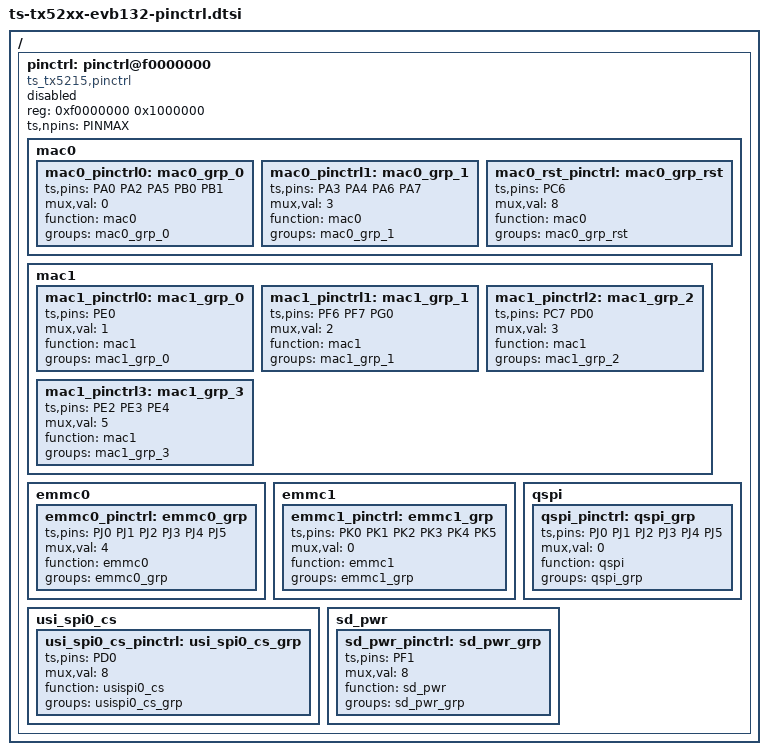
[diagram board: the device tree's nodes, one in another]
// SPDX-License-Identifier: GPL-2.0+
/*
 * Pinctrl specification for Tsingmicor Soc
 *
 * (C) Copyright 2022 - 2022, Tsingmicro, Inc.
 *
 */

#include <dt-bindings/pinctrl/pinctrl-ts-tx5215.h>
/ {
		pinctrl: pinctrl@f0000000 {
			compatible = "ts_tx5215,pinctrl";
			status = "disabled";
			reg = <0xf0000000 0x1000000>;
			ts,npins = <PINMAX>;
			mac0 {
				//MAC_EPHY_CLK MAC_TXEN MAC_RXDV MAC_MDC MAC_MDIO
				mac0_pinctrl0: mac0_grp_0 {
					ts,pins = <PA0 PA2 PA5 PB0 PB1>;
					mux,val = <0>;
					function = "mac0";
					groups = "mac0_grp_0";
				};
				//MAC_TXD0 MAC_TXD1 MAC_RXD0 MAC_RXD1
				mac0_pinctrl1: mac0_grp_1 {
					ts,pins = <PA3 PA4 PA6 PA7>;
					mux,val = <3>;
					function = "mac0";
					groups = "mac0_grp_1";
				};
				mac0_rst_pinctrl: mac0_grp_rst {
					ts,pins = <PC6>;
					mux,val = <8>;
					function = "mac0";
					groups = "mac0_grp_rst";
				};
			};

			mac1 {
				//MAC1_EPHY_CLK
				mac1_pinctrl0: mac1_grp_0 {
					ts,pins = <PE0>;
					mux,val = <1>;
					function = "mac1";
					groups = "mac1_grp_0";
				};
				//MAC1_TXEN MAC1_TXD0 MAC1_TXD1
				mac1_pinctrl1: mac1_grp_1 {
					ts,pins = <PF6 PF7 PG0>;
					mux,val = <2>;
					function = "mac1";
					groups = "mac1_grp_1";
				};
				//MAC1_MDC MAC1_MDIO
				mac1_pinctrl2: mac1_grp_2 {
					ts,pins = <PC7 PD0>;
					mux,val = <3>;
					function = "mac1";
					groups = "mac1_grp_2";
				};
				//MAC1_RXDV MAC1_RXD0 MAC1_RXD1
				mac1_pinctrl3: mac1_grp_3 {
					ts,pins = <PE2 PE3 PE4>;
					mux,val = <5>;
					function = "mac1";
					groups = "mac1_grp_3";
				};
			};

#if 0
			spi0 {
				spi0_pinctrl: spi0_grp {
					ts,pins = <PC0 PC1 PC2 PC3>;
					mux,val = <0>;
					function = "spi0";
					groups = "spi0_grp";
				};
			};
#endif
			emmc0 {
				emmc0_pinctrl: emmc0_grp {
					ts,pins = <PJ0 PJ1 PJ2 PJ3 PJ4 PJ5>;
					mux,val = <4>;
					function = "emmc0";
					groups = "emmc0_grp";
				};
			};

			emmc1 {
				emmc1_pinctrl: emmc1_grp {
					ts,pins = <PK0 PK1 PK2 PK3 PK4 PK5>;
					mux,val = <0>;
					function = "emmc1";
					groups = "emmc1_grp";
				};
			};

			qspi {
				qspi_pinctrl: qspi_grp {
					ts,pins = <PJ0 PJ1 PJ2 PJ3 PJ4 PJ5>;
					mux,val = <0>;
					function = "qspi";
					groups = "qspi_grp";
				};
			};

			usi_spi0_cs {
				usi_spi0_cs_pinctrl: usi_spi0_cs_grp {
					ts,pins = <PD0>;
					mux,val = <8>;
					function = "usispi0_cs";
					groups = "usispi0_cs_grp";
				};
			};
			sd_pwr {
				sd_pwr_pinctrl: sd_pwr_grp {
					ts,pins = <PF1>;
					mux,val = <8>;
					function = "sd_pwr";
					groups = "sd_pwr_grp";
				};
			};
		};
};
